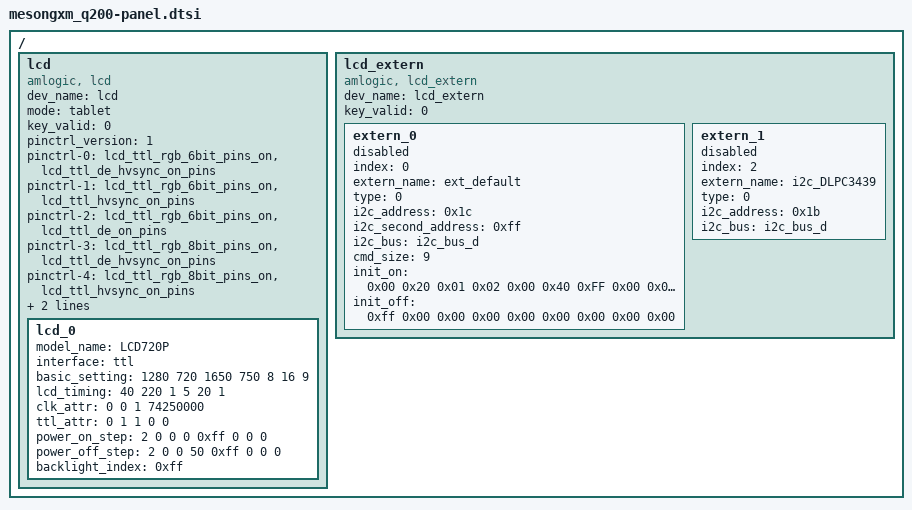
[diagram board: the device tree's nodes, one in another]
/*
 * arch/arm64/boot/dts/amlogic/mesongxm_q200-panel.dtsi
 *
 * Copyright (C) 2016 Amlogic, Inc. All rights reserved.
 *
 * This program is free software; you can redistribute it and/or modify
 * it under the terms of the GNU General Public License as published by
 * the Free Software Foundation; either version 2 of the License, or
 * (at your option) any later version.
 *
 * This program is distributed in the hope that it will be useful, but WITHOUT
 * ANY WARRANTY; without even the implied warranty of MERCHANTABILITY or
 * FITNESS FOR A PARTICULAR PURPOSE.  See the GNU General Public License for
 * more details.
 *
 */

/ {
	lcd{
		compatible = "amlogic, lcd";
		dev_name = "lcd";
		mode = "tablet";
		status = "okay";
		key_valid = <0>;
		/* clocks = <&clkc CLKID_VCLK2_ENCL
		 *	&clkc CLKID_VCLK2_VENCL>;
		 * clock-names = "vencl_top",
		 * "vencl_int";
		 */
		pinctrl_version = <1>; /* for uboot */
		pinctrl-names = "ttl_6bit_hvsync_de_on","ttl_6bit_hvsync_on",
			"ttl_6bit_de_on","ttl_8bit_hvsync_de_on",
			"ttl_8bit_hvsync_on","ttl_8bit_de_on";
		pinctrl-0 = <&lcd_ttl_rgb_6bit_pins_on
			&lcd_ttl_de_hvsync_on_pins>;
		pinctrl-1 = <&lcd_ttl_rgb_6bit_pins_on
			&lcd_ttl_hvsync_on_pins>;
		pinctrl-2 = <&lcd_ttl_rgb_6bit_pins_on
			&lcd_ttl_de_on_pins>;
		pinctrl-3 = <&lcd_ttl_rgb_8bit_pins_on
			&lcd_ttl_de_hvsync_on_pins>;
		pinctrl-4 = <&lcd_ttl_rgb_8bit_pins_on
			&lcd_ttl_hvsync_on_pins>;
		pinctrl-5 = <&lcd_ttl_rgb_8bit_pins_on
			&lcd_ttl_de_on_pins>;

		/* power type:
		 *    (0=cpu_gpio, 1=pmu_gpio, 2=signal,3=extern, 0xff=ending)
		 * power index:
		 *    (point gpios_index, or extern_index,0xff=invalid)
		 * power value:(0=output low, 1=output high, 2=input)
		 * power delay:(unit in ms)
		 */
		/*lcd_cpu-gpios = <&gpio GPIOX_3 1>;*/
		/*lcd_cpu_gpio_names = "GPIOX_3";*/

		lcd_0{
			model_name = "LCD720P";
				/*interface(ttl,lvds,mipi)*/
			interface = "ttl";
				/* basic_setting:
				 * h_active,v_active,h_period,v_period,
				 * lcd_bits,screen_widht,screen_height
				 */
			basic_setting = <1280 720 1650 750 8 16 9>;
				/* lcd_timing:
				 * hs_width,hs_bp,hs_pol,vs_width,vs_bp,vs_pol
				 */
			lcd_timing = <40 220 1 5 20 1>;
				/* clk_attr:
				 * fr_adj_type(0=clock,1=htotal,2=vtotal),
				 * clk_ss_level,clk_auto_generate,
				 * pixel_clk(unit in Hz)
				 */
			clk_attr = <0 0 1 74250000>;
				/* ttl_attr:
				 * clk_pol, de_valid, hvsync_valid,
				 * rb_swap, bit_swap
				 */
			ttl_attr = <0 1 1 0 0>;
				/* power step: type,index,value,delay(ms) */
			power_on_step = <2 0 0 0
					0xff 0 0 0>;		
			power_off_step = <2 0 0 50
					0xff 0 0 0>;
			backlight_index = <0xff>;
		};
	};

	lcd_extern{
		compatible = "amlogic, lcd_extern";
		dev_name = "lcd_extern";
		status = "okay";
		key_valid = <0>;

		extern_0{
			index = <0>;
			extern_name = "ext_default";
			status = "disabled";
			type = <0>; /* 0=i2c, 1=spi, 2=mipi */
			i2c_address = <0x1c>; /* 7bit i2c address */
			i2c_second_address = <0xff>; /* 7bit i2c address, 0xff for none */
			i2c_bus = "i2c_bus_d";
			cmd_size = <9>;
			/* init on/off: (type, value..., delay), must match cmd_size for every group */
			/* type: 0x00=cmd(bit[3:0]=1 for second_addr), 0x10=gpio, 0xff=ending*/
			/* value: i2c or spi cmd, or gpio index & level, fill 0x0 for no use */
			/* delay: unit ms */
			init_on = <0x00 0x20 0x01 0x02 0x00 0x40 0xFF 0x00 0x00
				0x00 0x80 0x02 0x00 0x40 0x62 0x51 0x73 0x00
				0x00 0x61 0x06 0x00 0x00 0x00 0x00 0x00 0x00
				0x00 0xC1 0x05 0x0F 0x00 0x08 0x70 0x00 0x00
				0x00 0x13 0x01 0x00 0x00 0x00 0x00 0x00 0x00
				0x00 0x3D 0x02 0x01 0x00 0x00 0x00 0x00 0x00
				0x00 0xED 0x0D 0x01 0x00 0x00 0x00 0x00 0x00
				0x00 0x23 0x02 0x00 0x00 0x00 0x00 0x00 0x0A
				0xff 0x00 0x00 0x00 0x00 0x00 0x00 0x00 0x00>;
			init_off = <0xff 0x00 0x00 0x00 0x00 0x00 0x00 0x00 0x00>;
		};

		extern_1{
			index = <2>;
			extern_name = "i2c_DLPC3439";
			status = "disabled";
			type = <0>; /* 0=i2c, 1=spi, 2=mipi */
			i2c_address = <0x1b>; /* 7bit i2c address */
			i2c_bus = "i2c_bus_d";
		};
	};
};/* end of panel */

